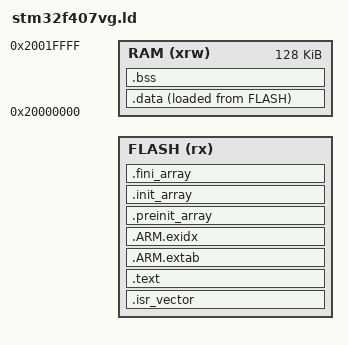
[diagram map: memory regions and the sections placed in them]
/* STM32F407VG reference. Flash origin and size are supplied by the build.
   CCM SRAM is intentionally unused. */
ENTRY(Reset_Handler)
MEMORY { FLASH (rx) : ORIGIN = TP_FLASH_ORIGIN, LENGTH = TP_FLASH_LENGTH
         RAM (xrw) : ORIGIN = 0x20000000, LENGTH = 128K }
_estack = ORIGIN(RAM) + LENGTH(RAM);
SECTIONS {
  .isr_vector : { KEEP(*(.isr_vector)) } > FLASH
  ASSERT((ADDR(.isr_vector) & 511) == 0, "vector table must be 512-byte aligned")
  .text : { *(.text*) *(.rodata*) KEEP(*(.init)) KEEP(*(.fini)) . = ALIGN(4); } > FLASH
  .ARM.extab : { *(.ARM.extab*) } > FLASH
  .ARM.exidx : { __exidx_start = .; *(.ARM.exidx*) __exidx_end = .; } > FLASH
  .preinit_array : { PROVIDE_HIDDEN(__preinit_array_start = .); KEEP(*(.preinit_array*)) PROVIDE_HIDDEN(__preinit_array_end = .); } > FLASH
  .init_array : { PROVIDE_HIDDEN(__init_array_start = .); KEEP(*(SORT(.init_array.*))) KEEP(*(.init_array*)) PROVIDE_HIDDEN(__init_array_end = .); } > FLASH
  .fini_array : { PROVIDE_HIDDEN(__fini_array_start = .); KEEP(*(SORT(.fini_array.*))) KEEP(*(.fini_array*)) PROVIDE_HIDDEN(__fini_array_end = .); } > FLASH
  _sidata = LOADADDR(.data);
  .data : { . = ALIGN(4); _sdata = .; *(.data*) . = ALIGN(4); _edata = .; } > RAM AT > FLASH
  .bss (NOLOAD) : { . = ALIGN(4); _sbss = .; *(.bss*) *(COMMON) . = ALIGN(4); _ebss = .; } > RAM
  . = ALIGN(8); _end = .; end = .;
  ASSERT(_end <= _estack - 4096, "RAM leaves less than 4 KiB for main stack")
}
